# nrf9220_cellcore register map
Vendor: Nordic Semiconductor; Series: nRF92; File version: 1
CPU: CM33 r0p4, little endian, MPU, FPU, 3 interrupt priority bits, 480 interrupts, 8 SAU regions
Registers are 32-bit, read-write, reset 0x0 unless marked. A register's access mark holds for its fields unless they carry their own. Offsets are from the block's base; [hi:lo] are bit positions; 'fields as' and 'values as' point back to an identical list.

## AESLTE_NS — AES-128 HW accelerator for LTE L2 security and MAC 0
Base 0x44008000
Same registers: AESLTE_S 0x54008000
0x00 TASKS_STARTGATHER wo — Start input DMA
  [0] TASKS_STARTGATHER
    1=Trigger task
0x04 TASKS_STOPGATHER wo — Stop input DMA
  [0] TASKS_STOPGATHER
    1=Trigger task
0x08 TASKS_STARTSCATTER wo — Start output DMA
  [0] TASKS_STARTSCATTER
    1=Trigger task
0x0C TASKS_STOPSCATTER wo — Stop output DMA
  [0] TASKS_STOPSCATTER
    1=Trigger task
0x10 TASKS_INITIALIZEAES wo — New keys (and IV) ready to be used, reset keybytes, ivbytes
  [0] TASKS_INITIALIZEAES
    1=Trigger task
0x14 TASKS_STARTOPERATION wo — Start cipher / MAC calculation depending on MODE
  [0] TASKS_STARTOPERATION
    1=Trigger task
0x18 TASKS_FINALIZEMAC wo — Finalize MAC calculation
  [0] TASKS_FINALIZEMAC
    1=Trigger task
0x1C TASKS_RESET wo — Stop all transfers and crypto operations (initialize) NOTE! SW must take care that AES is in inactive state when issuing SW reset.
  [0] TASKS_RESET
    1=Trigger task
0x100 EVENTS_GATHERSTARTED — Input DMA started
  [0] EVENTS_GATHERSTARTED
    0=NotGenerated (Event not generated); 1=Generated (Event generated)
0x104 EVENTS_GATHERDONE — Input DMA done
  [0] EVENTS_GATHERDONE
    values as EVENTS_GATHERSTARTED.EVENTS_GATHERSTARTED
0x108 EVENTS_SCATTERSTARTED — Output DMA started
  [0] EVENTS_SCATTERSTARTED
    values as EVENTS_GATHERSTARTED.EVENTS_GATHERSTARTED
0x10C EVENTS_SCATTERDONE — Output DMA done
  [0] EVENTS_SCATTERDONE
    values as EVENTS_GATHERSTARTED.EVENTS_GATHERSTARTED
0x110 EVENTS_IVREADY — IV received (ivbytes == 16)
  [0] EVENTS_IVREADY
    values as EVENTS_GATHERSTARTED.EVENTS_GATHERSTARTED
0x114 EVENTS_AESINITIALIZED — New keys and IV taken into use
  [0] EVENTS_AESINITIALIZED
    values as EVENTS_GATHERSTARTED.EVENTS_GATHERSTARTED
0x118 EVENTS_MESSAGEREADY — LENGTH == 0
  [0] EVENTS_MESSAGEREADY
    values as EVENTS_GATHERSTARTED.EVENTS_GATHERSTARTED
0x11C EVENTS_MACREADY — MAC calculated
  [0] EVENTS_MACREADY
    values as EVENTS_GATHERSTARTED.EVENTS_GATHERSTARTED
0x120 EVENTS_RESETTED — Resetted (all transfers and crypto operations stopped)
  [0] EVENTS_RESETTED
    values as EVENTS_GATHERSTARTED.EVENTS_GATHERSTARTED
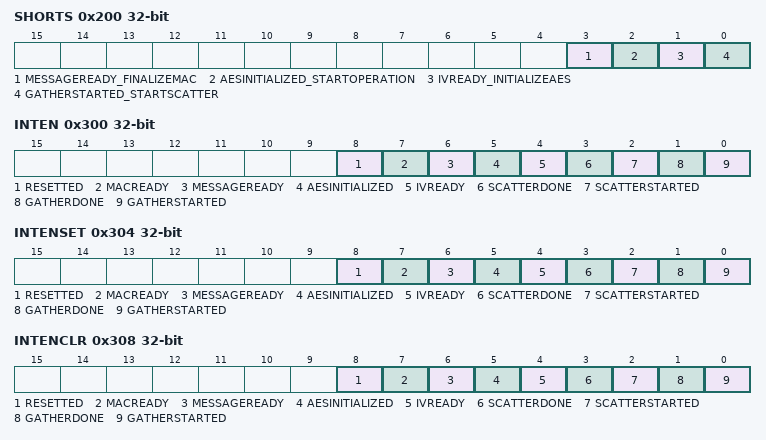
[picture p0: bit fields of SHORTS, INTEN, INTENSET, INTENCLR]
0x200 SHORTS — Shortcuts between local events and tasks
  [all] fields
    0=Disabled (Disable shortcut); 1=Enabled (Enable shortcut)
  [3] MESSAGEREADY_FINALIZEMAC — Shortcut between event MESSAGEREADY and task FINALIZEMAC
  [2] AESINITIALIZED_STARTOPERATION — Shortcut between event AESINITIALIZED and task STARTOPERATION
  [1] IVREADY_INITIALIZEAES — Shortcut between event IVREADY and task INITIALIZEAES
  [0] GATHERSTARTED_STARTSCATTER — Shortcut between event GATHERSTARTED and task STARTSCATTER
0x300 INTEN — Enable or disable interrupt
  [all] fields
    0=Disabled; 1=Enabled
  [8] RESETTED — Enable or disable interrupt for event RESETTED
  [7] MACREADY — Enable or disable interrupt for event MACREADY
  [6] MESSAGEREADY — Enable or disable interrupt for event MESSAGEREADY
  [5] AESINITIALIZED — Enable or disable interrupt for event AESINITIALIZED
  [4] IVREADY — Enable or disable interrupt for event IVREADY
  [3] SCATTERDONE — Enable or disable interrupt for event SCATTERDONE
  [2] SCATTERSTARTED — Enable or disable interrupt for event SCATTERSTARTED
  [1] GATHERDONE — Enable or disable interrupt for event GATHERDONE
  [0] GATHERSTARTED — Enable or disable interrupt for event GATHERSTARTED
0x304 INTENSET — Enable interrupt
  [all] fields
    on read: 0=Disabled (Read: Disabled); 1=Enabled (Read: Enabled) | on write: 1=Set (Enable)
  [8] RESETTED — Write '1' to enable interrupt for event RESETTED
  [7] MACREADY — Write '1' to enable interrupt for event MACREADY
  [6] MESSAGEREADY — Write '1' to enable interrupt for event MESSAGEREADY
  [5] AESINITIALIZED — Write '1' to enable interrupt for event AESINITIALIZED
  [4] IVREADY — Write '1' to enable interrupt for event IVREADY
  [3] SCATTERDONE — Write '1' to enable interrupt for event SCATTERDONE
  [2] SCATTERSTARTED — Write '1' to enable interrupt for event SCATTERSTARTED
  [1] GATHERDONE — Write '1' to enable interrupt for event GATHERDONE
  [0] GATHERSTARTED — Write '1' to enable interrupt for event GATHERSTARTED
0x308 INTENCLR — Disable interrupt
  [all] fields
    on read: 0=Disabled (Read: Disabled); 1=Enabled (Read: Enabled) | on write: 1=Clear (Disable)
  [8] RESETTED — Write '1' to disable interrupt for event RESETTED
  [7] MACREADY — Write '1' to disable interrupt for event MACREADY
  [6] MESSAGEREADY — Write '1' to disable interrupt for event MESSAGEREADY
  [5] AESINITIALIZED — Write '1' to disable interrupt for event AESINITIALIZED
  [4] IVREADY — Write '1' to disable interrupt for event IVREADY
  [3] SCATTERDONE — Write '1' to disable interrupt for event SCATTERDONE
  [2] SCATTERSTARTED — Write '1' to disable interrupt for event SCATTERSTARTED
  [1] GATHERDONE — Write '1' to disable interrupt for event GATHERDONE
  [0] GATHERSTARTED — Write '1' to disable interrupt for event GATHERSTARTED
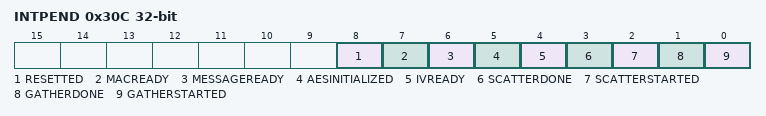
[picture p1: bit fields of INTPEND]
0x30C INTPEND ro — Pending interrupts
  [all] fields
    on read: 0=NotPending (Read: Not pending); 1=Pending (Read: Pending)
  [8] RESETTED — Read pending status of interrupt for event RESETTED
  [7] MACREADY — Read pending status of interrupt for event MACREADY
  [6] MESSAGEREADY — Read pending status of interrupt for event MESSAGEREADY
  [5] AESINITIALIZED — Read pending status of interrupt for event AESINITIALIZED
  [4] IVREADY — Read pending status of interrupt for event IVREADY
  [3] SCATTERDONE — Read pending status of interrupt for event SCATTERDONE
  [2] SCATTERSTARTED — Read pending status of interrupt for event SCATTERSTARTED
  [1] GATHERDONE — Read pending status of interrupt for event GATHERDONE
  [0] GATHERSTARTED — Read pending status of interrupt for event GATHERSTARTED
0x400 LENGTH — Keystream length in bits (Cipher), message length in bits (MAC)
0x404 MODE
  [0] MODE — Mode (0 == Cipher, 1 == MAC)
    0=Ciphering mode; 1=MAC (CMAC mode)
0x408 BURSTMODE — Selection for DMA burst mode
  [0] BURSTMODE — Burst mode select.
    0=Burst (Use burst mode); 1=Single (Use single transactions)
0x600 MAC0 ro — EIA2 MAC W0, first word of 128-bit MAC
0x604 MAC1 ro — EIA2 MAC W1, second word of 128-bit MAC
0x608 MAC2 ro — EIA2 MAC W2, third word of 128-bit MAC
0x60C MAC3 ro — EIA2 MAC W3, fourth word of 128-bit MAC
0x800 INJOBPTR — Input job pointer
0x900 OUTJOBPTR — Output job pointer
